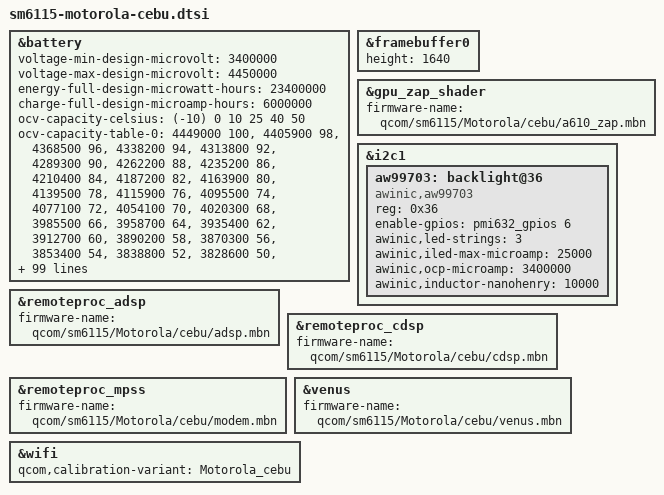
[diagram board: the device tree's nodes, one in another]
// SPDX-License-Identifier: (GPL-2.0+ OR BSD-3-Clause)
/*
 * Copyright (c) 2026, Val Packett <val@packett.cool>
 */

#include "sm6115.dtsi"
#include "sm6115-motorola-common.dtsi"

&battery {
	voltage-min-design-microvolt = <3400000>;
	voltage-max-design-microvolt = <4450000>;
	energy-full-design-microwatt-hours = <23400000>;
	charge-full-design-microamp-hours = <6000000>;

	ocv-capacity-celsius = <(-10) 0 10 25 40 50>;

	ocv-capacity-table-0 =
		<4449000 100>, <4405900 98>, <4368500 96>, <4338200 94>,
		<4313800 92>, <4289300 90>, <4262200 88>, <4235200 86>,
		<4210400 84>, <4187200 82>, <4163900 80>, <4139500 78>,
		<4115900 76>, <4095500 74>, <4077100 72>, <4054100 70>,
		<4020300 68>, <3985500 66>, <3958700 64>, <3935400 62>,
		<3912700 60>, <3890200 58>, <3870300 56>, <3853400 54>,
		<3838800 52>, <3828600 50>, <3821500 48>, <3815400 46>,
		<3809800 44>, <3804700 42>, <3799300 40>, <3793800 38>,
		<3788300 36>, <3782700 34>, <3777100 32>, <3771100 30>,
		<3764700 28>, <3757800 26>, <3750500 24>, <3742500 22>,
		<3733700 20>, <3723700 18>, <3712200 16>, <3700300 14>,
		<3690100 12>, <3681200 10>, <3676900 9>, <3672800 8>,
		<3668600 7>, <3663400 6>, <3652800 5>, <3628600 4>,
		<3581700 3>, <3505800 2>, <3377500 1>;

	ocv-capacity-table-1 =
		<4448000 100>, <4409700 98>, <4376200 96>, <4348700 94>,
		<4326000 92>, <4303000 90>, <4278300 88>, <4253200 86>,
		<4227800 84>, <4202200 82>, <4177700 80>, <4154200 78>,
		<4131600 76>, <4109700 74>, <4088400 72>, <4067300 70>,
		<4046800 68>, <4025100 66>, <4000400 64>, <3974300 62>,
		<3949700 60>, <3925800 58>, <3904100 56>, <3884900 54>,
		<3867600 52>, <3852300 50>, <3838500 48>, <3826100 46>,
		<3814200 44>, <3804400 42>, <3798100 40>, <3793400 38>,
		<3789000 36>, <3785000 34>, <3780800 32>, <3776000 30>,
		<3770600 28>, <3764600 26>, <3757900 24>, <3750100 22>,
		<3739800 20>, <3727900 18>, <3714700 16>, <3698700 14>,
		<3683000 12>, <3672200 10>, <3668100 9>, <3664200 8>,
		<3659200 7>, <3650400 6>, <3630000 5>, <3586400 4>,
		<3515000 3>, <3408900 2>, <3241000 1>;

	ocv-capacity-table-2 =
		<4447000 100>, <4411200 98>, <4379800 96>, <4353400 94>,
		<4331500 92>, <4309100 90>, <4284900 88>, <4260200 86>,
		<4235500 84>, <4210700 82>, <4186400 80>, <4162400 78>,
		<4138900 76>, <4115900 74>, <4093500 72>, <4072000 70>,
		<4051300 68>, <4031200 66>, <4012500 64>, <3993800 62>,
		<3971200 60>, <3944100 58>, <3919700 56>, <3899500 54>,
		<3881700 52>, <3866500 50>, <3853300 48>, <3841300 46>,
		<3830200 44>, <3820000 42>, <3810500 40>, <3801800 38>,
		<3794400 36>, <3787800 34>, <3782400 32>, <3778400 30>,
		<3774800 28>, <3770100 26>, <3763900 24>, <3756600 22>,
		<3747400 20>, <3736300 18>, <3722500 16>, <3707500 14>,
		<3690100 12>, <3681600 10>, <3678000 9>, <3675000 8>,
		<3669400 7>, <3660200 6>, <3636900 5>, <3588900 4>,
		<3521200 3>, <3430500 2>, <3284000 1>;

	ocv-capacity-table-3 =
		<4445500 100>, <4410900 98>, <4380200 96>, <4354100 94>,
		<4332100 92>, <4309700 90>, <4285600 88>, <4261200 86>,
		<4236700 84>, <4212100 82>, <4187700 80>, <4163600 78>,
		<4140100 76>, <4117100 74>, <4094800 72>, <4073100 70>,
		<4052100 68>, <4031800 66>, <4012900 64>, <3994400 62>,
		<3974500 60>, <3953400 58>, <3932000 56>, <3908800 54>,
		<3887400 52>, <3872000 50>, <3859600 48>, <3848300 46>,
		<3837700 44>, <3828000 42>, <3819200 40>, <3811200 38>,
		<3803900 36>, <3797200 34>, <3790600 32>, <3783600 30>,
		<3776400 28>, <3768600 26>, <3760300 24>, <3752100 22>,
		<3744600 20>, <3735600 18>, <3723100 16>, <3710200 14>,
		<3693500 12>, <3689000 10>, <3687300 9>, <3685300 8>,
		<3682400 7>, <3675100 6>, <3648800 5>, <3600000 4>,
		<3535000 3>, <3444800 2>, <3304300 1>;

	ocv-capacity-table-4 =
		<4443000 100>, <4409300 98>, <4379200 96>, <4353400 94>,
		<4331500 92>, <4309200 90>, <4285400 88>, <4261200 86>,
		<4236900 84>, <4212400 82>, <4188300 80>, <4164400 78>,
		<4141000 76>, <4118300 74>, <4096300 72>, <4075000 70>,
		<4054300 68>, <4034200 66>, <4014900 64>, <3995700 62>,
		<3975800 60>, <3955100 58>, <3934200 56>, <3911500 54>,
		<3890200 52>, <3874900 50>, <3862500 48>, <3851200 46>,
		<3840100 44>, <3830300 42>, <3822400 40>, <3815400 38>,
		<3808200 36>, <3800200 34>, <3792700 32>, <3786300 30>,
		<3779800 28>, <3771800 26>, <3762000 24>, <3752000 22>,
		<3742400 20>, <3731800 18>, <3719100 16>, <3706700 14>,
		<3690300 12>, <3686000 10>, <3685100 9>, <3684100 8>,
		<3681800 7>, <3672900 6>, <3645500 5>, <3596000 4>,
		<3529800 3>, <3442400 2>, <3314400 1>;

	ocv-capacity-table-5 =
		<4440500 100>, <4407200 98>, <4377100 96>, <4351200 94>,
		<4328900 92>, <4306200 90>, <4281800 88>, <4257100 86>,
		<4232700 84>, <4208300 82>, <4184300 80>, <4160500 78>,
		<4137200 76>, <4114400 74>, <4092200 72>, <4070700 70>,
		<4049800 68>, <4029800 66>, <4011100 64>, <3993100 62>,
		<3974800 60>, <3956700 58>, <3937100 56>, <3913300 54>,
		<3890200 52>, <3874400 50>, <3862100 48>, <3851100 46>,
		<3840700 44>, <3831000 42>, <3822200 40>, <3814000 38>,
		<3806600 36>, <3800300 34>, <3793400 32>, <3783600 30>,
		<3772100 28>, <3761300 26>, <3750900 24>, <3741100 22>,
		<3732800 20>, <3723600 18>, <3711000 16>, <3697800 14>,
		<3683500 12>, <3680200 10>, <3678900 9>, <3677000 8>,
		<3674100 7>, <3664700 6>, <3633800 5>, <3583300 4>,
		<3516600 3>, <3423000 2>, <3282100 1>;
};

&framebuffer0 {
	height = <1640>;
};

&gpu_zap_shader {
	firmware-name = "qcom/sm6115/Motorola/cebu/a610_zap.mbn";
};

&i2c1 {
	status = "okay";

	aw99703: backlight@36 {
		compatible = "awinic,aw99703";
		reg = <0x36>;

		enable-gpios = <&pmi632_gpios 6 GPIO_ACTIVE_HIGH>;

		awinic,led-strings = <3>;
		awinic,iled-max-microamp = <25000>;
		awinic,ocp-microamp = <3400000>;
		awinic,inductor-nanohenry = <10000>;
	};
};

&remoteproc_adsp {
	firmware-name = "qcom/sm6115/Motorola/cebu/adsp.mbn";
	status = "okay";
};

&remoteproc_cdsp {
	firmware-name = "qcom/sm6115/Motorola/cebu/cdsp.mbn";
	status = "okay";
};

&remoteproc_mpss {
	firmware-name = "qcom/sm6115/Motorola/cebu/modem.mbn";
	status = "okay";
};

&venus {
	firmware-name = "qcom/sm6115/Motorola/cebu/venus.mbn";
	status = "okay";
};

&wifi {
	qcom,calibration-variant = "Motorola_cebu";
};
